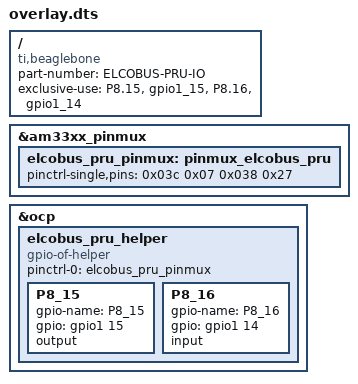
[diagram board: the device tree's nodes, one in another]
/dts-v1/;
/plugin/;

/ {
	compatible = "ti,beaglebone", "ti,beaglebone-black";

	part-number = "ELCOBUS-PRU-IO";

	exclusive-use =
		"P8.15", "gpio1_15",
		"P8.16", "gpio1_14";

	fragment@0 {
		target = <&am33xx_pinmux>;
		__overlay__ {
			elcobus_pru_pinmux: pinmux_elcobus_pru {
				pinctrl-single,pins = <
					0x03c 0x07 // P8_15 (GPIO1_15): mode 7 (gpio), pull down, Rx disabled
					0x038 0x27 // P8_16 (GPIO1_14): mode 7 (gpio), pull down, Rx enabled
				>;
			};
		};
	};

	fragment@1 {
		target = <&ocp>;
		__overlay__ {
			elcobus_pru_helper {
				compatible = "gpio-of-helper";
				pinctrl-names = "default";
				pinctrl-0 = <&elcobus_pru_pinmux>;
				status = "okay";

				P8_15 {
					gpio-name = "P8_15";
					gpio = <&gpio1 15 0>;
					output;
				};
				P8_16 {
					gpio-name = "P8_16";
					gpio = <&gpio1 14 0>;
					input;
				};
			};
		};
	};
};
